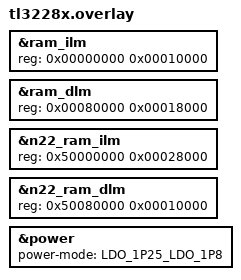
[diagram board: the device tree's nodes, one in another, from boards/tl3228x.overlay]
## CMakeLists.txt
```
# SPDX-License-Identifier: Apache-2.0

cmake_minimum_required(VERSION 3.20.0)

find_package(Zephyr REQUIRED HINTS $ENV{ZEPHYR_BASE})
project(tpll_prx)



target_sources(app PRIVATE src/main.c 
                           src/tpll_event.c                       
                           )
```

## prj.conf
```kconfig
CONFIG_BT=y
CONFIG_BT_TLX=y
CONFIG_SOC_RISCV_TELINK_TL322X=y
CONFIG_TELINK_TL322X_ENABLE_N22=y 
```

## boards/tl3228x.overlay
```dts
/*
 * Copyright (c) 2026 Telink Semiconductor
 *
 * SPDX-License-Identifier: Apache-2.0
 */

/* Memory layout override (values match board defaults, kept for clarity) */
&ram_ilm {
	reg = <0x00000000 0x00010000>;
};

&ram_dlm {
	reg = <0x00080000 0x00018000>;
};

&n22_ram_ilm {
	reg = <0x50000000 0x00028000>;
};

&n22_ram_dlm {
	reg = <0x50080000 0x00010000>;
};


&power {
	power-mode = "LDO_1P25_LDO_1P8";
};
```

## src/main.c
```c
/*
 * Copyright (c) 2012-2014 Wind River Systems, Inc.
 *
 * SPDX-License-Identifier: Apache-2.0
 */

#include <stdio.h>
#include "tl_common.h"
#include "stack/2p4g/tpll/tpll.h"
#include "stack/multicore_comm/service/service_d25f.h"
#include <zephyr/kernel.h>
#include "tpll_event.h"
#include <tlx_bt.h>
#include "stack/2p4g/tl_tpll/tl_tpll.h"
#define LOG_LEVEL LOG_LEVEL_DBG
#include <zephyr/logging/log.h>
LOG_MODULE_REGISTER(tpll_prx);

volatile uint32_t loop;
volatile u8 debug_data[16] = {0x29, 0x11, 0x22, 0x33, 0x44, 0x55, 0x66, 0x77};


extern uint32_t hci_recv_cnt;

int main(void)
{
	int status;

	printf("Telink %s TPLL PRX Sample\n", CONFIG_BOARD_TARGET);

	mcc_d25f_register_shm_recv_cb(TLK_SHM_MSG_2P4G, pri_hci_handler_d25f);

	status = tlx_bt_controller_init();
	if (status) {
		LOG_ERR("Bluetooth controller init failed %d", status);
		return status;
	}

    uint8_t base_address_0[4] = {0x41, 0x76, 0x71, 0xe7};
    uint8_t base_address_1[4] = {0xe7, 0xe7, 0xe7, 0xe7};
    uint8_t addr_prefix[8] = {0x29, 0x11, 0x22, 0x33, 0x44, 0x55, 0x66, 0x77};

	//setting
	d25f_2p4g_set_mode(TPLL_MODE_PRX);
	d25f_2p4g_set_bitrate(TPLL_BITRATE_2MBPS);
	d25f_2p4g_apply_config();
	d25f_2p4g_set_access_code_len(ADDRESS_WIDTH_5BYTES);
	d25f_2p4g_set_access_code(TPLL_PIPE0, (u8 *)base_address_0, ADDRESS_WIDTH_4BYTES);
	d25f_2p4g_set_access_code(TPLL_PIPE1, (u8 *)base_address_1, ADDRESS_WIDTH_4BYTES);
	d25f_2p4g_set_prefixes(0x08, addr_prefix, sizeof(addr_prefix));
	d25f_2p4g_set_rf_channel(14);
	d25f_2p4g_enable_pipes(0xff);
	d25f_2p4g_set_status(TPLL_STATUS_RX_BUSY);
	d25f_2p4g_start_rx();
	irq_enable(1);


	while (1) {

		k_sem_take(&tpll_event_sem, K_FOREVER);

		if (d25f_2p4g_get_last_event() == N22_2P4G_CMD_START_RX_STA) {
			tl_tpll_payload_t *payload = d25f_2p4g_get_rx_payload();
			printf("RX data len=%d: ", payload->length);
			for (int i = 0; i < payload->length && i < 32; i++) {
				printf("%02x ", payload->data[i]);
			}
			printf("\n");
			loop++;
		}
	}

	return 0;
}
```

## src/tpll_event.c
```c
#include "tl_common.h"
#include "stack/multicore_comm/service/service_d25f.h"
#include "stack/2p4g/tl_tpll/tl_tpll.h"
#include "tpll_event.h"

volatile uint32_t hci_recv_cnt = 0,hci_recv_n22_cnt = 0;
static volatile uint8_t tpll_status = TPLL_STATUS_IDLE;

K_SEM_DEFINE(tpll_event_sem, 0, 1);

static volatile d25f_2p4g_cmd_e last_event;
static tl_tpll_payload_t last_rx_payload;


void pri_hci_handler_d25f(u8 *p, unsigned short int n)
{
	// printf("hci_recv_cnt %d, n %d, d %x  %x\n", hci_recv_cnt, n, p[0], p[1]);


    u8 cmd       = p[1];
    u8 param_len = p[2];
    u8 *param    = &p[3];
    if ((n - D25F_2P4G_CMD_HEADER_LEN) < param_len) {
        return -1;
    }

    switch (cmd)
    {
    case N22_2P4G_CMD_START_RX_STA:
		hci_recv_cnt++;
		last_event = N22_2P4G_CMD_START_RX_STA;
		if (param_len >= sizeof(tl_tpll_payload_t)) {
			memcpy(&last_rx_payload, param, sizeof(tl_tpll_payload_t));
		}
		k_sem_give(&tpll_event_sem);

		hci_recv_n22_cnt = *((uint32_t *)&last_rx_payload.data[188]);
        break;

    case N22_2P4G_CMD_START_TX_STA:
		last_event = N22_2P4G_CMD_START_TX_STA;
		k_sem_give(&tpll_event_sem);
		d25f_2p4g_set_status(TPLL_STATUS_IDLE);
        break;

    default:
        break;
    }


}

static int d25f_2p4g_send_cmd(d25f_2p4g_cmd_e cmd, const u8 *param, u8 param_len)
{
	u8 buf[D25F_2P4G_CMD_HEADER_LEN + 255];

	buf[0] = HCI_TYPE_CMD;
	buf[1] = (u8)cmd;
	buf[2] = param_len;
	if (param && param_len) {
		memcpy(&buf[3], param, param_len);
	}
	return (mcc_d25f_pri_send_msg(buf, D25F_2P4G_CMD_HEADER_LEN + param_len) == SHM_FIFO_SUCCESS)
		       ? 0 : -1;
}

int d25f_2p4g_set_mode(tpll_rf_mode_t mode)
{
	u8 param = (u8)mode;
	return d25f_2p4g_send_cmd(N22_2P4G_CMD_SET_MODE, &param, 1);
}

int d25f_2p4g_set_bitrate(uint8_t bitrate)
{
	u8 param = bitrate;
	return d25f_2p4g_send_cmd(N22_2P4G_CMD_SET_BITRATE, &param, 1);
}

int d25f_2p4g_set_retransmit(uint16_t count, uint16_t delay_us)
{
	u8 param[4];

	param[0] = count & 0xFF;
	param[1] = (count >> 8) & 0xFF;
	param[2] = delay_us & 0xFF;
	param[3] = (delay_us >> 8) & 0xFF;
	return d25f_2p4g_send_cmd(N22_2P4G_CMD_SET_RETRANSMIT, param, 4);
}

int d25f_2p4g_write_payload(uint8_t pipe, uint8_t *data, uint8_t len)
{
	u8 param[256];

	if (data == NULL || len == 0 || len > 255) {
		return -1;
	}
	param[0] = pipe;
	memcpy(&param[1], data, len);
	return d25f_2p4g_send_cmd(N22_2P4G_CMD_WRITE_PAYLOAD, param, 1 + len);
}

int d25f_2p4g_set_access_code_len(uint8_t length)
{
	u8 param = length;
	return d25f_2p4g_send_cmd(N22_2P4G_CMD_SET_ACCESS_CODE_LEN, &param, 1);
}

int d25f_2p4g_set_access_code(uint8_t pipe, uint8_t *addr, uint8_t len)
{
	u8 param[256];

	if (addr == NULL || len == 0 || len > 255) {
		return -1;
	}
	param[0] = pipe;
	memcpy(&param[1], addr, len);
	return d25f_2p4g_send_cmd(N22_2P4G_CMD_SET_ACCESS_CODE, param, 1 + len);
}

int d25f_2p4g_set_rf_channel(uint8_t channel)
{
	u8 param = channel;
	return d25f_2p4g_send_cmd(N22_2P4G_CMD_SET_RF_CHANNEL, &param, 1);
}

int d25f_2p4g_set_prefixes(uint8_t pipe_count, uint8_t *prefixes, uint8_t len)
{
	u8 param[256];

	if (prefixes == NULL || len == 0 || len > 255) {
		return -1;
	}
	param[0] = pipe_count;
	memcpy(&param[1], prefixes, len);
	return d25f_2p4g_send_cmd(N22_2P4G_CMD_SET_PREFIXES, param, 1 + len);
}

int d25f_2p4g_enable_pipes(uint8_t enable_mask)
{
	u8 param = enable_mask;
	return d25f_2p4g_send_cmd(N22_2P4G_CMD_ENABLE_PIPES, &param, 1);
}

int d25f_2p4g_apply_config(void)
{
	return d25f_2p4g_send_cmd(N22_2P4G_CMD_APPLY_CONFIG, NULL, 0);
}


int d25f_2p4g_start_tx(void)
{
	return d25f_2p4g_send_cmd(N22_2P4G_CMD_START_TX, NULL, 0);
}

int d25f_2p4g_start_rx(void)
{
	return d25f_2p4g_send_cmd(N22_2P4G_CMD_START_RX, NULL, 0);
}

void d25f_2p4g_set_status(uint8_t status)
{
	tpll_status = status;
}


uint8_t d25f_2p4g_get_status(void)
{
	return tpll_status;
}

d25f_2p4g_cmd_e d25f_2p4g_get_last_event(void)
{
	return last_event;
}

tl_tpll_payload_t *d25f_2p4g_get_rx_payload(void)
{
	return &last_rx_payload;
}
```

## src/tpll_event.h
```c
#ifndef _TPLL_EVENT_H_
#define _TPLL_EVENT_H_

#include <zephyr/kernel.h>
#include "tl_common.h"
#include "stack/2p4g/tl_tpll/tl_tpll.h"

/**
 * @brief       Dual-core 2.4G HCI command protocol definitions.
 *
 * Command packet format (Host core -> N22 core, via shared memory):
 *   byte 0: HCI_TYPE_CMD (0x01)      - type tag
 *   byte 1: cmd                         - sub-command opcode (@ref n22_2p4g_cmd_e)
 *   byte 2: param_len                   - parameter length (excluding header)
 *   byte 3..: param                     - parameter data
 *
 * Response packet format (N22 core -> Host core):
 *   byte 0: HCI_TYPE_CMD (0x01)
 *   byte 1: cmd                         - echoed sub-command opcode
 *   byte 2: status                      - execution status (0 = success, others = error code)
 */
#define D25F_2P4G_CMD_HEADER_LEN     3   /* HCI_TYPE_CMD + cmd + param_len */

typedef enum {
    N22_2P4G_CMD_SET_MODE           = 0x01, /* param: mode(1B) */
    N22_2P4G_CMD_SET_BITRATE        = 0x02, /* param: bitrate(1B) */
    N22_2P4G_CMD_SET_RETRANSMIT     = 0x03, /* param: count(2B LE) + delay_us(2B LE) */
    N22_2P4G_CMD_WRITE_PAYLOAD      = 0x04, /* param: pipe(1B) + data(NB) */
    N22_2P4G_CMD_SET_ACCESS_CODE_LEN= 0x05, /* param: length(1B) */
    N22_2P4G_CMD_SET_ACCESS_CODE    = 0x06, /* param: pipe(1B) + addr(NB) */
    N22_2P4G_CMD_SET_RF_CHANNEL     = 0x07, /* param: channel(1B) */
    N22_2P4G_CMD_SET_PREFIXES       = 0x08, /* param: num_pipes(1B) + prefixes(NB) */
    N22_2P4G_CMD_ENABLE_PIPES       = 0x09, /* param: enable_mask(1B) */
    N22_2P4G_CMD_APPLY_CONFIG       = 0x0A, /* param: none */
    N22_2P4G_CMD_START_RX           = 0x0B, /* param: none */
    N22_2P4G_CMD_START_TX           = 0x0C, /* param: none */
    N22_2P4G_CMD_START_RX_STA       = 0x0D, /* param: none */
    N22_2P4G_CMD_START_TX_STA       = 0x0E, /* param: none */
} d25f_2p4g_cmd_e;

/* TPLL status values returned by d25f_2p4g_get_status() */
#define TPLL_STATUS_IDLE        0x00
#define TPLL_STATUS_TX_BUSY     0x01
#define TPLL_STATUS_RX_BUSY     0x02




typedef enum {
	TPLL_RF_MODE_IDLE = 0,
	TPLL_RF_MODE_TX,
	TPLL_RF_MODE_RX,
} tpll_rf_mode_t;

typedef enum {
	TPLL_RF_CMD_MODE = 0x01,
	TPLL_RF_CMD_FREQ = 0x02,
	TPLL_RF_CMD_CHANNEL = 0x03,
	TPLL_RF_CMD_TX = 0x04,
} tpll_rf_cmd_t;

void pri_hci_handler_d25f(u8 *p, unsigned short int n);

int d25f_2p4g_set_mode(tpll_rf_mode_t mode);
int d25f_2p4g_set_bitrate(uint8_t bitrate);
int d25f_2p4g_set_retransmit(uint16_t count, uint16_t delay_us);
int d25f_2p4g_write_payload(uint8_t pipe, uint8_t *data, uint8_t len);
int d25f_2p4g_set_access_code_len(uint8_t length);
int d25f_2p4g_set_access_code(uint8_t pipe, uint8_t *addr, uint8_t len);
int d25f_2p4g_set_rf_channel(uint8_t channel);
int d25f_2p4g_set_prefixes(uint8_t pipe_count, uint8_t *prefixes, uint8_t len);
int d25f_2p4g_enable_pipes(uint8_t enable_mask);
int d25f_2p4g_apply_config(void);
int d25f_2p4g_start_rx(void);
int d25f_2p4g_start_tx(void);
uint8_t d25f_2p4g_get_status(void);
void d25f_2p4g_set_status(uint8_t status);

/** Semaphore signaled on N22_2P4G_CMD_START_RX_STA or N22_2P4G_CMD_START_TX_STA */
extern struct k_sem tpll_event_sem;

/** Returns the last event type (N22_2P4G_CMD_START_RX_STA / N22_2P4G_CMD_START_TX_STA) */
d25f_2p4g_cmd_e d25f_2p4g_get_last_event(void);

/** Returns pointer to the last received RX payload (valid only after RX_STA event) */
tl_tpll_payload_t *d25f_2p4g_get_rx_payload(void);

#endif /* _TPLL_EVENT_H_ */
```
